# ADC register map
Registers from a debugger description file.
Registers are 32-bit, read-only, no defined reset value unless marked. A register's access mark holds for its fields unless they carry their own. Addresses are absolute; registers are grouped by the start of their names; lines under a group give offsets from that group; [hi:lo] are bit positions; {n}, {i} and the like mark numbered series; 'fields as' and 'values as' point back to an identical list; <NAME> marks a mode.

## rADC
0x40065000 rADC_INTSTATUS0
  [15:0] bADC_INTSTATUS0_VC
0x40065004 rADC_INTSTATUS1
  [15:0] bADC_INTSTATUS1_VC
0x40065008 rADC_INTCLR access not given
  [15:0] bADC_INTCLR_VC
0x4006500C rADC_INTMASK access not given
  [15:0] bADC_INTMASK_VC
0x40065010 rADC_INTOVFSTATUS0
  [15:0] bADC_INTOVFSTATUS0_VC
0x40065014 rADC_INTOVFSTATUS1
  [15:0] bADC_INTOVFSTATUS1_VC
0x40065018 rADC_INTCLROVF access not given
  [15:0] bADC_INTCLROVF_VC
0x4006501C rADC_INTOVFMASK access not given
  [15:0] bADC_INTOVFMASK_VC
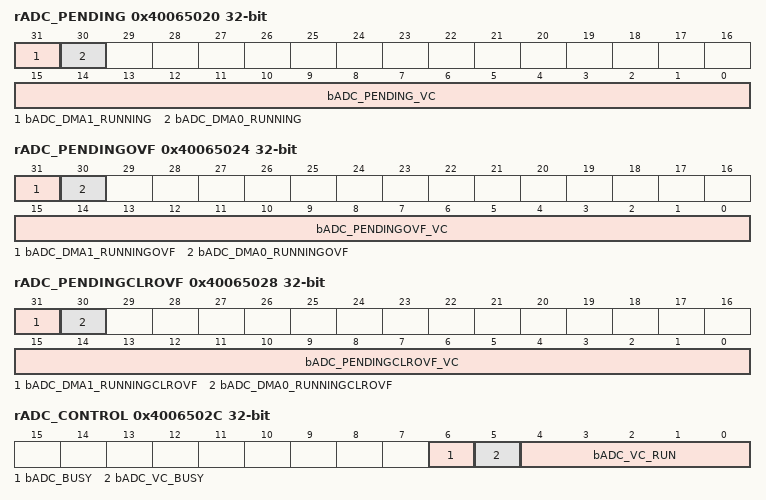
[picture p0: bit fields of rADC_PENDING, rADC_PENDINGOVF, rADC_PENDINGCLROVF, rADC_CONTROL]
0x40065020 rADC_PENDING
  [31] bADC_DMA1_RUNNING, [30] bADC_DMA0_RUNNING, [15:0] bADC_PENDING_VC
0x40065024 rADC_PENDINGOVF
  [31] bADC_DMA1_RUNNINGOVF, [30] bADC_DMA0_RUNNINGOVF, [15:0] bADC_PENDINGOVF_VC
0x40065028 rADC_PENDINGCLROVF access not given
  [31] bADC_DMA1_RUNNINGCLROVF, [30] bADC_DMA0_RUNNINGCLROVF, [15:0] bADC_PENDINGCLROVF_VC
0x4006502C rADC_CONTROL
  [6] bADC_BUSY, [5] bADC_VC_BUSY, [4:0] bADC_VC_RUN
0x40065030 rADC_FORCE
  [15:0] bADC_FORCE_VC
0x40065034 rADC_SETFORCE access not given
  [15:0] bADC_SETFORCE_VC
0x40065038 rADC_CLRFORCE access not given
  [15:0] bADC_CLRFORCE_VC
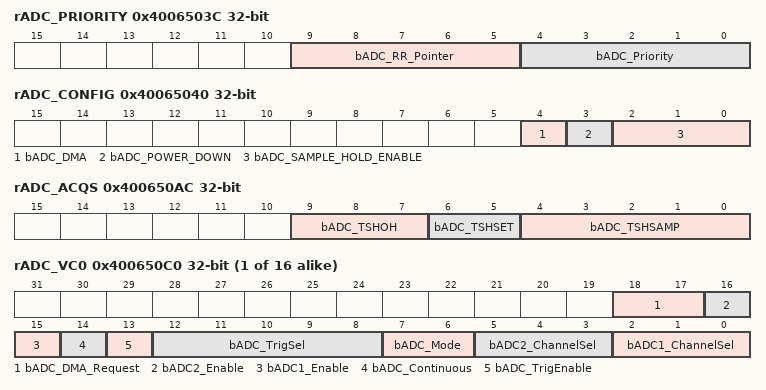
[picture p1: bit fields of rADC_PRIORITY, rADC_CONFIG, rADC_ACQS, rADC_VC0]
0x4006503C rADC_PRIORITY access not given
  [9:5] bADC_RR_Pointer, [4:0] bADC_Priority
0x40065040 rADC_CONFIG access not given
  [4] bADC_DMA, [3] bADC_POWER_DOWN, [2:0] bADC_SAMPLE_HOLD_ENABLE
0x400650AC rADC_ACQS access not given
  [9:7] bADC_TSHOH, [6:5] bADC_TSHSET, [4:0] bADC_TSHSAMP
{0x400650B0+4i} rADC_MASKLOCK{i} access not given (i=0..3)
  [15:0] bADC_MASKLOCK
{0x400650C0+4i} rADC_VC{i} access not given (i=0..15)
  [18:17] bADC_DMA_Request, [16] bADC2_Enable, [15] bADC1_Enable, [14] bADC_Continuous, [13] bADC_TrigEnable, [12:8] bADC_TrigSel, [7:6] bADC_Mode, [5:3] bADC2_ChannelSel, [2:0] bADC1_ChannelSel

## rADC1
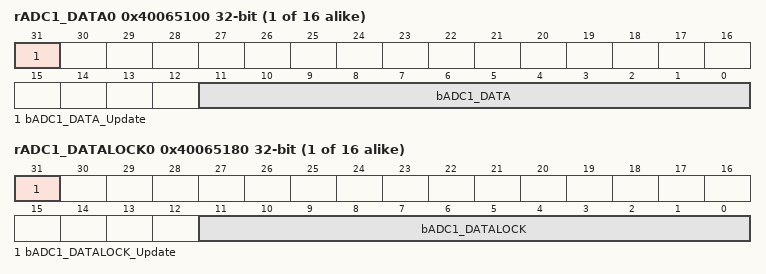
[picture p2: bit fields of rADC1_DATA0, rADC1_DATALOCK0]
{0x40065100+4i} rADC1_DATA{i} (i=0..15)
  [31] bADC1_DATA_Update, [11:0] bADC1_DATA
{0x40065180+4i} rADC1_DATALOCK{i} (i=0..15)
  [31] bADC1_DATALOCK_Update, [11:0] bADC1_DATALOCK

## rADC2
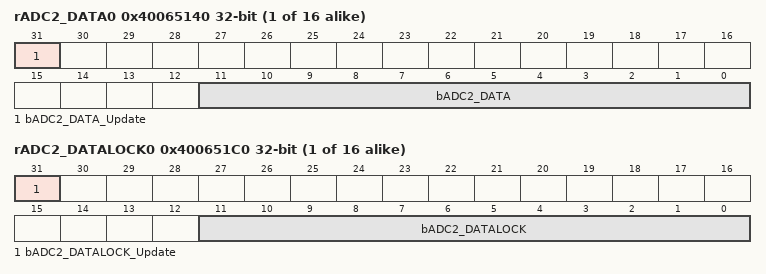
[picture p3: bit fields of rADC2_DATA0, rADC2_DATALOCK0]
{0x40065140+4i} rADC2_DATA{i} (i=0..15)
  [31] bADC2_DATA_Update, [11:0] bADC2_DATA
{0x400651C0+4i} rADC2_DATALOCK{i} (i=0..15)
  [31] bADC2_DATALOCK_Update, [11:0] bADC2_DATALOCK
